# nrf5340 register map
Vendor: Nordic Semiconductor; Series: nrf53; File version: 1
CPU: CM33 r0p2, little endian, MPU, FPU, 3 interrupt priority bits
Registers are 32-bit, read-write, reset 0x0 unless marked. A register's access mark holds for its fields unless they carry their own. Offsets are from the block's base; [hi:lo] are bit positions; lines under a group give offsets from that group; {n}, {i} and the like mark numbered series; 'fields as' and 'values as' point back to an identical list.

## FICR_NS — Factory Information Configuration Registers 0
Base 0x00FF0000
Same registers: FICR_S 0x00FF0000 (alternate view of FICR_NS)
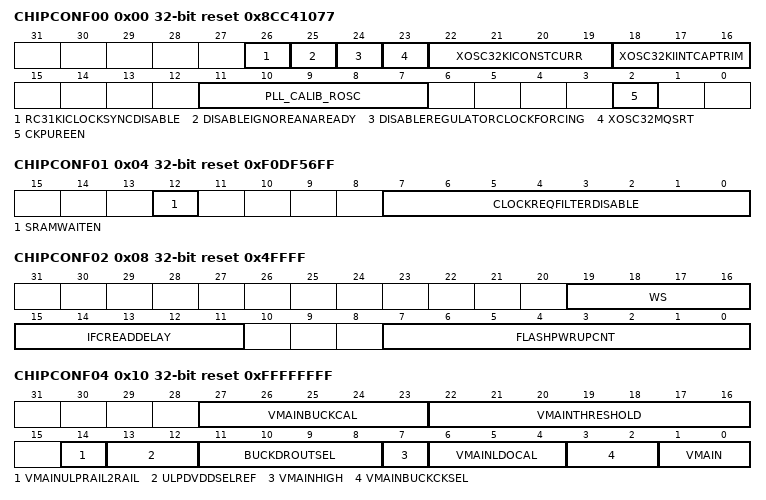
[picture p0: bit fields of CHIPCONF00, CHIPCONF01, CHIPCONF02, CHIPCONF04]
0x00 CHIPCONF00 ro reset 0x8CC41077 — Miscellaneous analog configuration. Will be set during production test.
  [26] RC31KICLOCKSYNCDISABLE — Disable synchronizer on calibration clock request from Rc32kiGenerator.
  [25] DISABLEIGNOREANAREADY
  [24] DISABLEREGULATORCLOCKFORCING
  [23] XOSC32MQSRT
  [22:19] XOSC32KICONSTCURR — Trimming for the XOC32KI oscillator when used in constant current mode
  [18:16] XOSC32KIINTCAPTRIM — On-chip capacitance trimming for the XOC32KI oscillator
    0=TRIM0 (0 percent); 1=TRIM12P5 (+12.5 percent); 2=TRIM25 (+25 percent); 3=NA0 (Forbidden); 4=NA1 (Forbidden); 5=NA2 (Forbidden); 6=TRIMM25 (-25 percent); 7=TRIMM12P5 (-12.5 percent)
  [11:7] PLL_CALIB_ROSC — HFCLK ring oscillator trim codes. Previous name: HFROSCTRIM.
  [2] CKPUREEN — Enable clock gate in clock purifier. Should always be 1.
0x04 CHIPCONF01 ro reset 0xF0DF56FF — Miscellaneous analog configuration. Will be set during production test.
  [12] SRAMWAITEN — Enable wait on ready upon accessing SRAM when turned on
  [7:0] CLOCKREQFILTERDISABLE — Disable glitch-filter on clock sources powerup and standby lines
    0=XOSC32M (Disable glitch-filter on powerUp- and standby lines to XOSC32M); 1=32ki (Disable glitch-filter on powerUp line to Rosc/Xosc/Synth used in clock system A (32ki)); 2=64M (Disable glitch-filter on powerUp line to PLL used in clock system B (64M)); 3=96M (Disable glitch-filter on powerUp line to PLL used in clock system C (96M)); 4=176M128M (Disable glitch-filter on powerUp line to PLL used in clock system D (176M/128M)); 5=MCPLL (Disable glitch-filter on powerUp line to PLL used in clock system E (MCPLL)); 6=192M (Disable glitch-filter on powerUp line to PLL used in clock system F (192M)); 7=12M (Disable glitch-filter on powerUp line to PLL used in clock system G (12M))
0x08 CHIPCONF02 ro reset 0x4FFFF — Miscellaneous analog configuration. Will be set during production test.
  [19:16] WS — Wait-states (excluding the cache controller) for I-Code flash access, D-Code has one more wait-state.
    {v}={v}WS ({v} wait-state in total for I-Code ({v+1} for D-Code)) (v=1..15)
  [15:11] IFCREADDELAY — number of cycles before Information Configuration Registers can be read
  [7:0] FLASHPWRUPCNT — Number of successful FLASHPWRUPn read cycles when powering up flash. After chip power up, the NVMC controller reads FLASHPWRUPn for 7 us.
0x0C CHIPCONF03 ro reset 0xFFFFFFFF — Miscellaneous analog configuration. Will be set during production test.
  [12:8] COMPREFTRIM — Calibrate internal bandgap reference in COMP
0x10 CHIPCONF04 ro reset 0xFFFFFFFF — Configuration for VREGMAIN. Will be set during production test.
  [27:23] VMAINBUCKCAL — VREGMAIN BUCK output voltage calibration Output voltage calibration. 0 : Minimum output voltage level. 31: Maximum output voltage level.
  [22:16] VMAINTHRESHOLD — Sets the threshold value for VREGMAIN
  [14] VMAINULPRAIL2RAIL — DVDD0V9 LDO mode 0 - NMOS only input stage in LDO (default) 1 - Rail2rail input stage in LDO
  [13:12] ULPDVDDSELREF — Output voltage calibration. 0: 0.75V ratio of AVDD1V3 output (default) 1: 0.75V reference 2: AVDD1V3 as reference. 3: Reserved for future use.
  [11:8] BUCKDROUTSEL — 0: Minimum driver speed, low efficiency, low noise. 7: Medium driver speed, medium efficiency, medium noise. 15: Maximum driver speed, high efficiency, high noise.
  [7] VMAINHIGH — Enable or disable the feature
    0=Disabled (Nominal output levels of VREGMAIN LDO); 1=Enabled (Increased output levels of VREGMAIN LDO)
  [6:4] VMAINLDOCAL — VREGMAIN LDO Output voltage calibration
  [3:2] VMAINBUCKCKSEL — VREGMAIN Buck Input clock selection.
    0=NORMAL (normal clock); 1=INVERTED (inverted clock)
  [1:0] VMAIN — VREGMAIN Output voltage selection.
    0=1V00 (1.00 V); 1=1V09 (1.09 V); 2=1V17 (1.17 V); 3=1V26 (1.26 V)
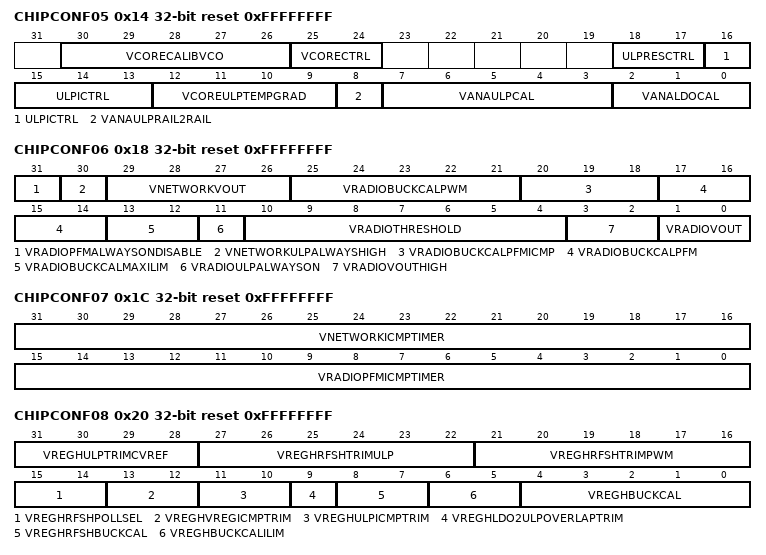
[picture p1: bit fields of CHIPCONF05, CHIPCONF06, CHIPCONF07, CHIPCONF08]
0x14 CHIPCONF05 ro reset 0xFFFFFFFF — Configuration for VREGANA. Will be set during production test.
  [30:26] VCORECALIBVCO — Internal oscillator calibration word 0: Low output frequency. 15: Default output frequency. 31: High output frequency.
  [25:24] VCORECTRL — Spare digital signals
  [18:17] ULPRESCTRL — Output voltage calibration. 0: switched with internal oscillator (default). 1: switched with CLK2K input 2: force always on. 3: force off (PWRUPs must be 0 otherwise default).
  [16:13] ULPICTRL — 0: minimum current. 7: default. 15: maximum current.
  [12:9] VCOREULPTEMPGRAD — Adjusts temperature gradient of reference (to compensate for modelling inaccuracy) 0: most negative gradient. 7: default. 15: most positive gradient.
  [8] VANAULPRAIL2RAIL — AVDD1V3 LDO mode 0: NMOS only input stage in LDO (default) 1: Rail2rail input stage in LDO
  [7:3] VANAULPCAL — VREGANA ULP Output voltage calibration
    0=min voltage; 7=max voltage
  [2:0] VANALDOCAL — VREGANA Output voltage calibration
0x18 CHIPCONF06 ro reset 0xFFFFFFFF — Configuration for VREGRADIO and VREGNETWORK. Will be set during production test.
  [31] VRADIOPFMALWAYSONDISABLE
  [30] VNETWORKULPALWAYSHIGH — Control the output voltage for VREGNETWORK (DVDD_0V9)
  [29:26] VNETWORKVOUT — Control the output voltage for VREGNETWORK (DVDD_0V9)
  [25:21] VRADIOBUCKCALPWM
  [20:18] VRADIOBUCKCALPFMICMP
  [17:14] VRADIOBUCKCALPFM
  [13:12] VRADIOBUCKCALMAXILIM
  [11] VRADIOULPALWAYSON — Force VREGRADIO ULP regulators to be always on
  [10:4] VRADIOTHRESHOLD — TBD for VREGRADIO (AVDD_1V3)
  [3:2] VRADIOVOUTHIGH — Control the TBD for VREGRADIO (AVDD_1V3)
  [1:0] VRADIOVOUT — Control the output voltage for VREGRADIO (AVDD_1V3)
0x1C CHIPCONF07 ro reset 0xFFFFFFFF — ICMP timeer configuration for VREGRADIO and VREGNETWORK. Will be set during production test.
  [31:16] VNETWORKICMPTIMER — Control the stay-alive time for the VNETWORK current comparator (DVDD_0V9)
  [15:0] VRADIOPFMICMPTIMER — Control the stay-alive time for the VRADIO PFM current comparator
0x20 CHIPCONF08 ro reset 0xFFFFFFFF — Configuration for VREGH. Will be set during production test.
  [31:28] VREGHULPTRIMCVREF
  [27:22] VREGHRFSHTRIMULP — Trimmed value for refresh mode counter for automatic mode change to ULP
  [21:16] VREGHRFSHTRIMPWM — Trimmed value for refresh mode counter for automatic mode change to PWM
  [15:14] VREGHRFSHPOLLSEL — Programmable value for counter for poller in PWM mode
    0=256 us polling interval; 1=512 us polling interval; 2=1024 us polling interval; 3=Disabled
  [13:12] VREGHVREGICMPTRIM — Trimming of VREG_VIO load current measurement
    0=m30pcnt (-30 percent); 1=m10pcnt (-10 percent (default)); 2=p10pcnt (+10 percent); 3=p30pcnt (+30 percent)
  [11:10] VREGHULPICMPTRIM — Trimming of VREGH_ULP load current measurement
    values as VREGHVREGICMPTRIM
  [9] VREGHLDO2ULPOVERLAPTRIM — Programmable value for VREGH LDO to ULP overlay counter
    0=512 us overlay; 1=1024 us overlay
  [8:7] VREGHRFSHBUCKCAL — Refresh mode trim register
  [6:5] VREGHBUCKCALILIM — VREGH BUCK output current limit calibration
    0=65mA (default); 1=m20pcnt (-20 percent); 2=p40pcnt (+40 percent); 3=p20pcnt (+20 percent)
  [4:0] VREGHBUCKCAL — VREGH BUCK output voltage fine calibration
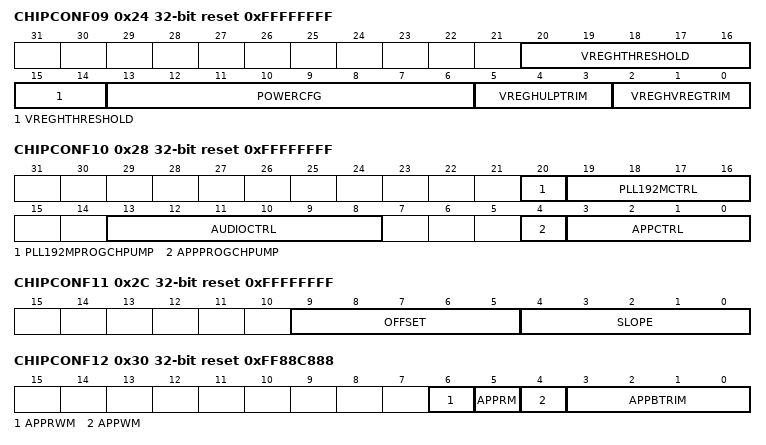
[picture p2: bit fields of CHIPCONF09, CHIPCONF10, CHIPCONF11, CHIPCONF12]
0x24 CHIPCONF09 ro reset 0xFFFFFFFF — Configuration for VREGH. Will be set during production test.
  [20:14] VREGHTHRESHOLD — Sets the threshold value for VREGH
  [13:6] POWERCFG — Power configuration for VREGH
  [5:3] VREGHULPTRIM — Output voltage trimming for VREGH _ULP
  [2:0] VREGHVREGTRIM — VREGH LDO output voltage trimming
0x28 CHIPCONF10 ro reset 0xFFFFFFFF — Configuration for Application, Audio and 192M PLLs,
  [20] PLL192MPROGCHPUMP — Power configuration for VREGH
  [19:16] PLL192MCTRL — Power configuration for VREGH
  [13:8] AUDIOCTRL — Power configuration for VREGH
  [4] APPPROGCHPUMP — Power configuration for VREGH
  [3:0] APPCTRL — Power configuration for VREGH
0x2C CHIPCONF11 ro reset 0xFFFFFFFF — Configuration for XOSC32M
  [9:5] OFFSET — Offset trim factor on integer form
  [4:0] SLOPE — Slope trim factor on 2's complement form
0x30 CHIPCONF12 reset 0xFF88C888 — Backdoor trim values for Application VMC
  [6] APPRWM — Read/Write Margin Adjustment
    0=Disabled; 1=Enabled
  [5] APPRM — Read Margin Adjustment
    0=Disabled; 1=Enabled
  [4] APPWM — Write Margin Adjustment
    0=Disabled; 1=Enabled
  [3:0] APPBTRIM — Source Bias Trim Adjustment for retention
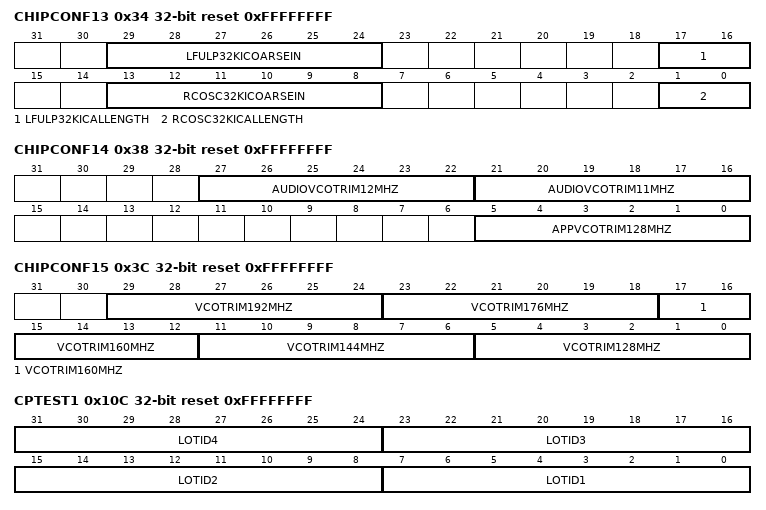
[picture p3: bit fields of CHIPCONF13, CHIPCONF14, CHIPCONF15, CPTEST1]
0x34 CHIPCONF13 reset 0xFFFFFFFF — RCOSC32K trim values
  [29:24] LFULP32KICOARSEIN — LFULP coarse calibration input
  [17:16] LFULP32KICALLENGTH — 32kHz ULP RC oscillator calibration length in number of cycles
    0=N64 (64 cycles); 1=N128 (128 cycles); 2=N256 (256 cycles); 3=N512 (512 cycles)
  [13:8] RCOSC32KICOARSEIN — RCOSC coarse calibration input
  [1:0] RCOSC32KICALLENGTH — 32kHz RC oscillator calibration length in number of cycles
    values as LFULP32KICALLENGTH
0x38 CHIPCONF14 reset 0xFFFFFFFF — Trim values for Application and Audio PLL
  [27:22] AUDIOVCOTRIM12MHZ — Trim value for the Audio PLL VCO at 12.288MHz
  [21:16] AUDIOVCOTRIM11MHZ — Trim value for the Audio PLL VCO at 11.289MHz
  [5:0] APPVCOTRIM128MHZ — Trim value for the Application PLL VCO at 128MHz
0x3C CHIPCONF15 reset 0xFFFFFFFF — Trim values for the 192M PLL
  [29:24] VCOTRIM192MHZ — Trim value for the 192M PLL VCO at 192MHz
  [23:18] VCOTRIM176MHZ — Trim value for the 192M PLL VCO at 176MHz
  [17:12] VCOTRIM160MHZ — Trim value for the 192M PLL VCO at 160MHz
  [11:6] VCOTRIM144MHZ — Trim value for the 192M PLL VCO at 144MHz
  [5:0] VCOTRIM128MHZ — Trim value for the 192M PLL VCO at 128MHz
{0xF0+4i} FLASHPWRUP{i} ro reset 0xAAAAAAAA (i=0..3) — Power-up pattern for flash
0x100 TESTSTATUS ro reset 0xFFFFFFFF — Code memory test status. Will be set during production test.
0x104 CPTEST0 ro reset 0xFFFFFFFF — Result from Circuit Probe test
  [31:0] CP1
0x108 CPTEST00 ro reset 0xFFFFFFFF — Result from Circuit Probe test
  [31:0] CP2
0x10C CPTEST1 ro reset 0xFFFFFFFF — Result from Circuit Probe test
  [31:24] LOTID4 — 4th ascii byte of Lot ID character
  [23:16] LOTID3 — 3rd ascii byte of Lot ID character
  [15:8] LOTID2 — 2nd ascii byte of Lot ID character
  [7:0] LOTID1 — 1st ascii byte of Lot ID character
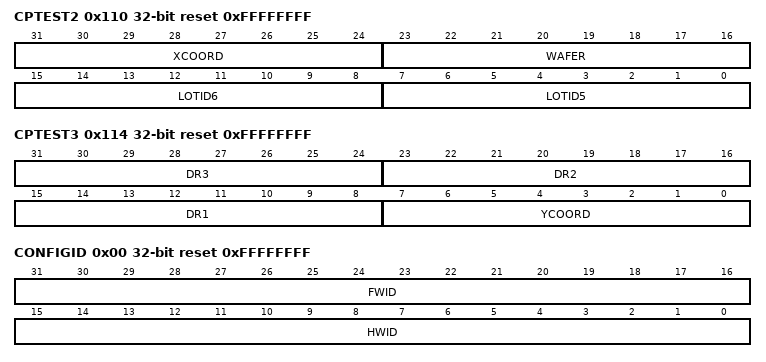
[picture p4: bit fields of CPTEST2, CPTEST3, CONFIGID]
0x110 CPTEST2 ro reset 0xFFFFFFFF — Result from Circuit Probe test
  [31:24] XCOORD — Device X-coordinate, always >=0, offset so that the leftmost value on wafer is 0
  [23:16] WAFER — Wafer number, 1 byte integer
  [15:8] LOTID6 — 6th ascii byte of Lot ID character
  [7:0] LOTID5 — 5th ascii byte of Lot ID character
0x114 CPTEST3 ro reset 0xFFFFFFFF — Result from Circuit Probe test
  [31:24] DR3 — Data Retention (DR) flag
  [23:16] DR2 — Data Retention (DR) flag
  [15:8] DR1 — Data Retention (DR) flag
  [7:0] YCOORD — Device Y-coordinate, always >=0, offset so that the bottom value on wafer is 0
0x118 CPTEST4 ro reset 0xFFFFFFFF — Result from Circuit Probe test
  [7:0] DR4 — Data Retention (DR) flag
{0x108+4i} CPTEST{i} ro reset 0xFFFFFFFF (i=5..8) — Result from Circuit Probe test, flash repair information
  [31:0] CPTEST{i} — flash repair information
0x200 INFO group — Device info
  0x00 CONFIGID ro reset 0xFFFFFFFF — Configuration identifier
    [31:16] FWID — Deprecated field - Identification number for the FW that is pre-loaded into the chip
    [15:0] HWID — Identification number for the HW
  {0x4+4j} DEVICEID[{j}] (j=0..1) ro reset 0xFFFFFFFF — Description collection: Device identifier
    [31:0] DEVICEID — 64 bit unique device identifier
  0x0C PART ro reset 0x5340 — Part code
    [31:0] PART
      0x5340=N5340 (nRF5340); 0xFFFFFFFF=Unspecified
  0x10 VARIANT ro reset 0x41414141 — Part Variant, Hardware version and Production configuration
    [31:0] VARIANT — Part Variant, Hardware version and Production configuration, encoded as ASCII
      0x41414141=AAAA; 0xFFFFFFFF=Unspecified
  0x14 PACKAGE ro reset 0xFFFFFFFF — Package option
    [31:0] PACKAGE
      0x2005=CK (CKxx - 7x8 WLCSP 56 balls with backside coating for light protection); 0xFFFFFFFF=Unspecified
  0x18 RAM ro reset 0x40 — RAM variant
    [31:0] RAM
      16=K16 (16 kByte RAM); 32=K32 (32 kByte RAM); 64=K64 (64 kByte RAM); 0xFFFFFFFF=Unspecified
  0x1C FLASH ro reset 0x200 — Flash variant
    [31:0] FLASH
      128=K128 (128 kByte FLASH); 0x100=K256 (256 kByte FLASH); 0x200=K512 (512 kByte FLASH); 0xFFFFFFFF=Unspecified
  0x20 CODEPAGESIZE ro reset 0xFFFFFFFF — Code memory page size in bytes
  0x24 CODESIZE ro reset 0xFFFFFFFF — Code memory size
    [31:0] CODESIZE — Code memory size in number of pages
  0x28 DEVICETYPE ro reset 0xFFFFFFFF
    [31:0] DEVICETYPE
      0=Die (Device is an physical DIE); 0xFFFFFFFF=FPGA (Device is an FPGA)
0x230 PARTNO ro reset 0xFFFFFFFF — Part number of the device. Will be updated in production test.
0x234 HWREVISION ro reset 0xFFFFFFFF — Hardware Revision of the device. Will be updated in production test.
0x238 PRODUCTIONREVISION ro reset 0xFFFFFFFF — Production revision of the device. Will be updated in production test.
{0x300+8i} TRIMCNF[{i}] (i=0..31) group — Unspecified
  0x00 ADDR ro — Description cluster: Address
    [31:0] Address
  0x04 DATA ro — Description cluster: Data
{0x800+4i} PRODTEST[{i}] (i=0..2) ro reset 0xFFFFFFFF — Description collection: Production test signature n
  [31:0] PRODTEST — Production test signature n A majority vote is done by HW for each bit over all three PRODTEST fields in order to read the valid value
    0xBB42319F=Done (Production tests done DFT mode blocked); 0xFFFFFFFF=NotDone (Production tests not done DFT mode open)
0xC00 TRNG90B group — NIST800-90B RNG calibration data
  0x00 BYTES ro reset 0xFFFFFFFF — Amount of bytes for the required entropy bits
  0x04 RCCUTOFF ro reset 0xFFFFFFFF — Repetition counter cutoff
  0x08 APCUTOFF ro reset 0xFFFFFFFF — Adaptive proportion cutoff
  0x0C STARTUP ro reset 0x210 — Amount of bytes for the startup tests
  {0xC+4j} ROSC{j} ro reset 0xFFFFFFFF (j=1..4) — Sample count for ring oscillator {j}
